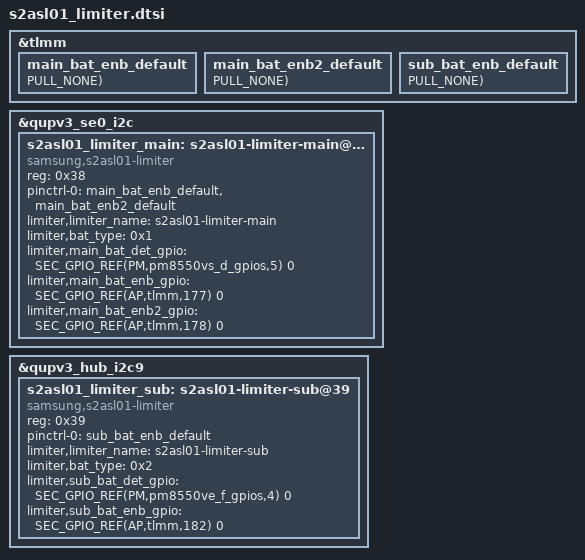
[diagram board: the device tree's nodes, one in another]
&tlmm {
	main_bat_enb_default: main_bat_enb_default {
		GPIO_CONFIG_PUD(AP,tlmm,177, FUNC_OUTPUT, PULL_NONE);
	};
};

&tlmm {
	main_bat_enb2_default: main_bat_enb2_default {
		GPIO_CONFIG_PUD(AP,tlmm,178, FUNC_OUTPUT, PULL_NONE);
	};
};

&tlmm {
	sub_bat_enb_default: sub_bat_enb_default {
		GPIO_CONFIG_PUD(AP,tlmm,182, FUNC_OUTPUT, PULL_NONE);
	};
};

&qupv3_se0_i2c {
	status = "okay";

	s2asl01_limiter_main: s2asl01-limiter-main@38 {
		compatible = "samsung,s2asl01-limiter";
		reg = <0x38>;
		status = "okay";
		pinctrl-names = "default";
		pinctrl-0 = <&main_bat_enb_default &main_bat_enb2_default>;

		limiter,limiter_name = "s2asl01-limiter-main";
		limiter,bat_type = <0x1>; /* LIMITER_MAIN */

		limiter,main_bat_det_gpio = <SEC_GPIO_REF(PM,pm8550vs_d_gpios,5) 0>;
		limiter,main_bat_enb_gpio = <SEC_GPIO_REF(AP,tlmm,177) 0>;
		limiter,main_bat_enb2_gpio = <SEC_GPIO_REF(AP,tlmm,178) 0>;
	};
};

&qupv3_hub_i2c9 {
	status = "okay";

	s2asl01_limiter_sub: s2asl01-limiter-sub@39 {
		compatible = "samsung,s2asl01-limiter";
		reg = <0x39>;
		status = "okay";
		pinctrl-names = "default";
		pinctrl-0 = <&sub_bat_enb_default>;

		limiter,limiter_name = "s2asl01-limiter-sub";
		limiter,bat_type = <0x2>; /* LIMITER_SUB */

		limiter,sub_bat_det_gpio = <SEC_GPIO_REF(PM,pm8550ve_f_gpios,4) 0>;
		limiter,sub_bat_enb_gpio = <SEC_GPIO_REF(AP,tlmm,182) 0>;
	};
};
